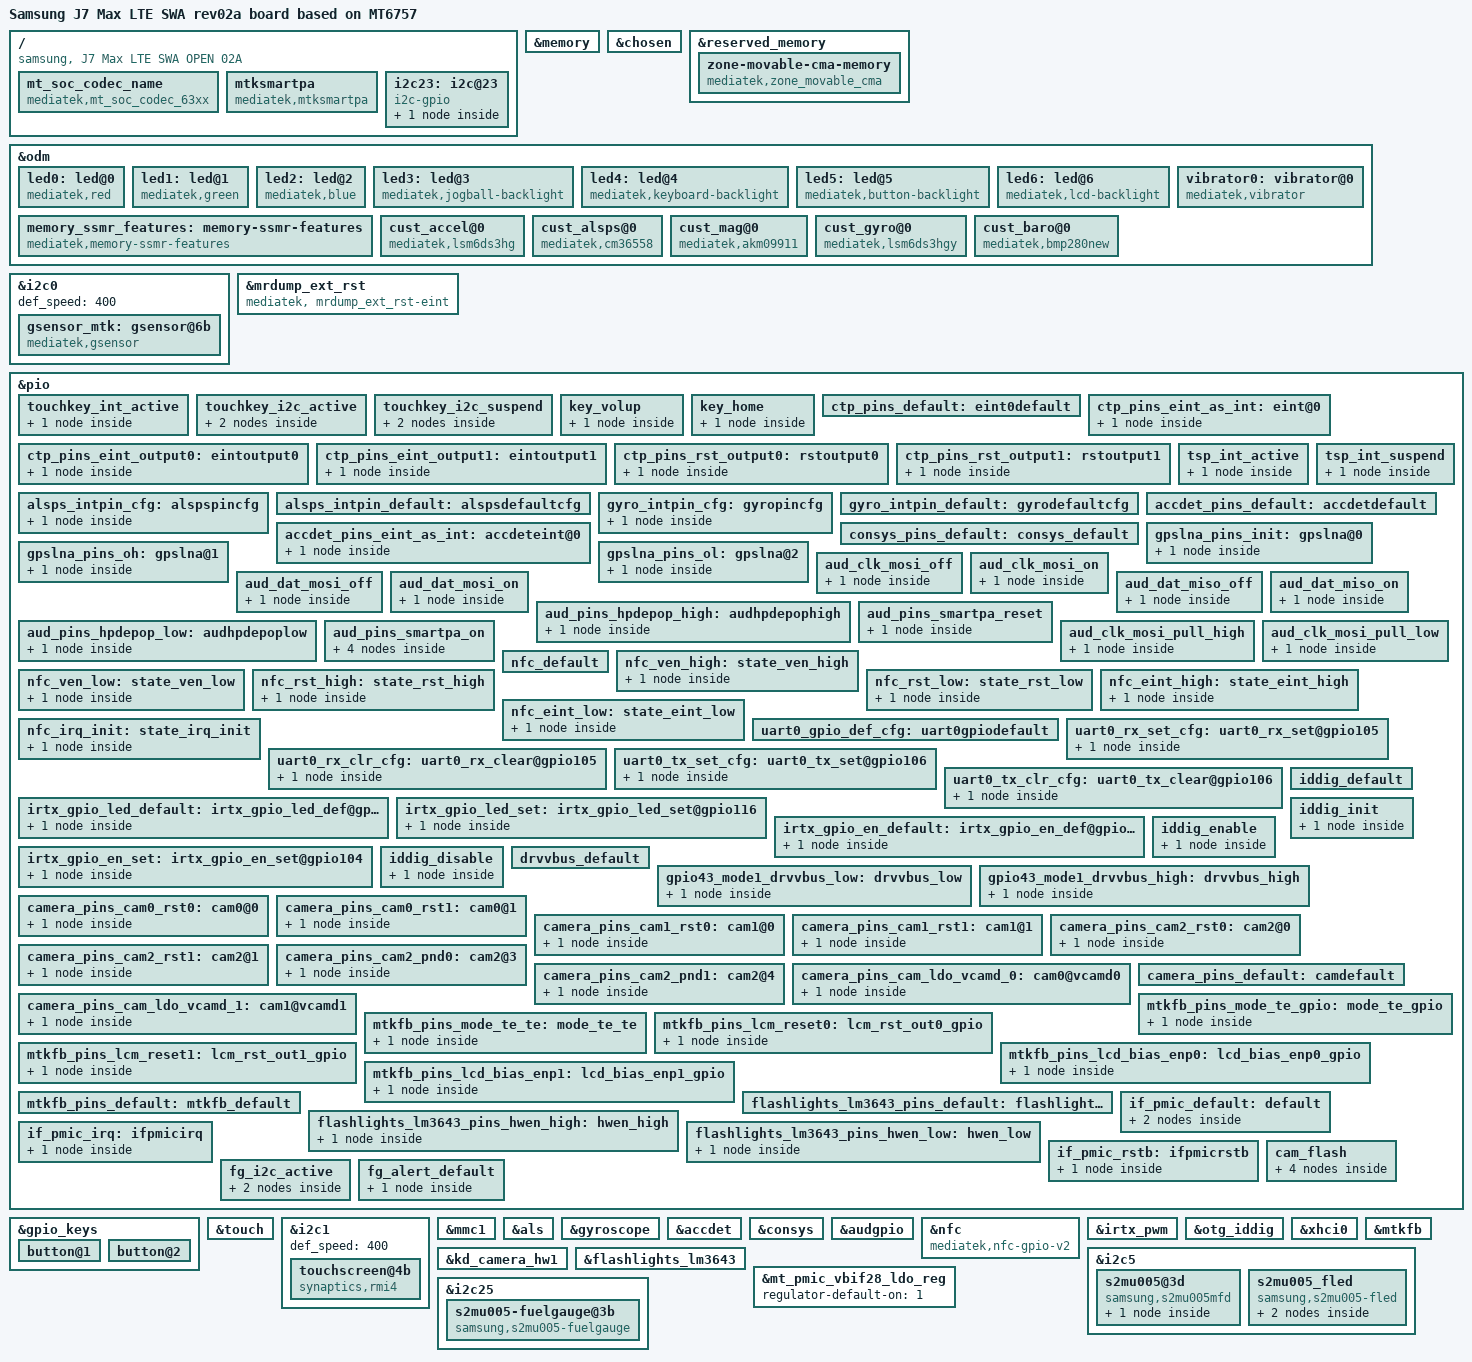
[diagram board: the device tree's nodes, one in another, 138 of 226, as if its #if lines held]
/*
 * Copyright (C) 2016 MediaTek Inc.
 *
 * This program is free software; you can redistribute it and/or modify
 * it under the terms of the GNU General Public License version 2 as
 * published by the Free Software Foundation.
 *
 * This program is distributed in the hope that it will be useful,
 * but WITHOUT ANY WARRANTY; without even the implied warranty of
 * MERCHANTABILITY or FITNESS FOR A PARTICULAR PURPOSE.
 * See http://www.gnu.org/licenses/gpl-2.0.html for more details.
 */

#include <generated/autoconf.h>
/dts-v1/;

#ifdef CONFIG_MTK_DTBO_FEATURE
/plugin/;
#include <dt-bindings/interrupt-controller/irq.h>
#include <dt-bindings/interrupt-controller/arm-gic.h>
#include <dt-bindings/mmc/mt6757-msdc.h>
#include <dt-bindings/pinctrl/mt6757-pinfunc.h>
#else
#include "mt6757.dts"
#include "titan6757_phone_gpio.dtsi"
#include <dt-bindings/input/input.h>
#include "battery_data_j7max_common.dtsi"
#endif

/ {
	model = "Samsung J7 Max LTE SWA rev02a board based on MT6757";
	model_info-chip = <6757>;
	model_info-platform = "android";
	model_info-subtype = "mediatek";
	model_info-hw_rev = <5>;
	model_info-hw_rev_end = <255>;
	compatible = "samsung, J7 Max LTE SWA OPEN 02A", "mediatek,MT6757";
};

&memory {
	device_type = "memory";
	reg = <0 0x40000000 0 0x1e605000>,
		  <1 0x00000000 0 0x20000000>;
};

/* chosen */
&chosen {
	bootargs = "console=tty0 console=ttyMT0,921600n1 root=/dev/ram initrd=0x45000000,
	0x1000000 loglevel=8 androidboot.selinux=permissive androidboot.hardware=mt6757";
	/* fpga may has no lk, we need to specify display info here */
	/* fb buffer is reserved using this dts by memory node above */
	atag,videolfb-fb_base_h = <0x0>;
	atag,videolfb-fb_base_l = <0x5e605000>;
	atag,videolfb-islcmfound = <1>;
	/* because no lk, so lcm is not inited */
	atag,videolfb-islcm_inited = <0>;
	atag,videolfb-fps= <6000>;
	atag,videolfb-vramSize= <0x017bb000>;
	atag,videolfb-lcmname= "nt35695_fhd_dsi_cmd_truly_nt50358_drv";
};


&reserved_memory {
	#address-cells = <2>;
	#size-cells = <2>;
	ranges;

	zone-movable-cma-memory {
		compatible = "mediatek,zone_movable_cma";
		size = <0 0x18000000>;
		/* 256MB alignment */
		alignment = <0 0x1000000>;
		alloc-ranges = <0 0xc0000000 1 0x00000000>;
	};
};

&odm {
	led0:led@0 {
		compatible = "mediatek,red";
		led_mode = <0>;
		data = <1>;
		pwm_config = <0 0 0 0 0>;
	};
	led1:led@1 {
		compatible = "mediatek,green";
		led_mode = <0>;
		data = <1>;
		pwm_config = <0 0 0 0 0>;
	};
	led2:led@2 {
		compatible = "mediatek,blue";
		led_mode = <0>;
		data = <1>;
		pwm_config = <0 0 0 0 0>;
	};
	led3:led@3 {
		compatible = "mediatek,jogball-backlight";
		led_mode = <0>;
		data = <1>;
		pwm_config = <0 0 0 0 0>;
	};
	led4:led@4 {
		compatible = "mediatek,keyboard-backlight";
		led_mode = <0>;
		data = <1>;
		pwm_config = <0 0 0 0 0>;
	};
	led5:led@5 {
		compatible = "mediatek,button-backlight";
		led_mode = <0>;
		data = <1>;
		pwm_config = <0 0 0 0 0>;
	};
	led6:led@6 {
		compatible = "mediatek,lcd-backlight";
		led_mode = <4>;
		data = <1>;
		pwm_config = <0 0 0 0 0>;
	};
	vibrator0:vibrator@0 {
		compatible = "mediatek,vibrator";
		vib_timer = <25>;
		vib_limit = <9>;
		vib_vol= <9>;
	};
	memory_ssmr_features: memory-ssmr-features {
		compatible = "mediatek,memory-ssmr-features";
		svp-size = <0 0x10000000>;
		iris-recognition-size = <0 0>;
		2d_fr-size = <0 0>;
		tui-size = <0 0x4000000>;
		wfd-size = <0 0x4000000>;
		prot-sharedmem-size = <0 0>;
	};
/*  start sensor */

	cust_accel@0 {
		compatible = "mediatek,lsm6ds3hg";
		i2c_num	= <0>;
		i2c_addr = <0x6b 0 0 0>;
		direction = <5>;
		power_id = <0xffff>;
		power_vol = <0>;
		firlen = <16>;
		is_batch_supported = <0>;
	};
	cust_alsps@0 {
		compatible = "mediatek,cm36558";
		i2c_num	= <1>;
		i2c_addr = <0x51 0 0 0>;
		polling_mode_ps	= <0>;
		polling_mode_als = <1>;
		power_id = <0xffff>;
		power_vol = <0>;
		als_level = <0 328 861 1377 3125 7721 7767 12621 23062 28430 33274 47116 57694 57694 65535>;
		als_value = <0 133 304 502 1004 2005 3058 5005 8008 10010 12000 16000 20000 20000 20000 20000>;
		ps_threshold_high = <26>;
		ps_threshold_low = <21>;
		is_batch_supported_ps = <0>;
		is_batch_supported_als = <0>;
	};
	cust_mag@0 {
		compatible			= "mediatek,akm09911";
		i2c_num				= <1>;
		/* i2c_addr			= <0x0D 0 0 0>; */
		direction			= <7>;
		power_id			= <0xffff>;
		power_vol			= <0>;
		/* is_batch_supported		= <0>; */
	};

	cust_gyro@0 {
		compatible			= "mediatek,lsm6ds3hgy";
		i2c_num				= <1>;
		/* i2c_addr			= <0x68 0 0 0>; */
		direction			= <7>;
		power_id			= <0xffff>;
		power_vol			= <0>;
		firlen				= <0>;
		is_batch_supported		= <0>;
	};

	cust_baro@0 {
		compatible			= "mediatek,bmp280new";
		i2c_num				= <1>;
		/* i2c_addr			= <0x77 0 0 0>; */
		direction			= <0>;
		power_id			= <0xffff>;
		power_vol			= <0>;
		firlen				= <32>;
		is_batch_supported		= <0>;
	};
/* end sensor */
};

&i2c0 {
	#address-cells = <1>;
	#size-cells = <0>;
	def_speed = <400>;
	gsensor_mtk:gsensor@6b {
		compatible = "mediatek,gsensor";
		reg = <0x6b>;
		direction = <5>;
		power_id = <0xffff>;
		power_vol = <0>;
		firlen = <16>;
		is_batch_supported = <0>;
		status = "okay";
	};
};

/ {
	/* start audio */
	mt_soc_codec_name {
		compatible = "mediatek,mt_soc_codec_63xx";
		use_hp_depop_flow = <1>; /* select 1: use, 0: not use */
		use_ul_260k = <0>; /* select 1: use, 0: not use */
		clk_src = <0>; /* select 1: external, 0: pmic internal */
	};

	mtksmartpa {
		compatible = "mediatek,mtksmartpa";
	};
	/* end audio */

	/*i2c-gpio and touch key*/
	i2c23: i2c@23 { /* SW I2C */
		cell-index = <23>;
		compatible = "i2c-gpio";
		gpios = <&pio 190 0 /* sda */
				&pio 191 0 /* scl */
				>;
		//i2c-gpio,sda-open-drain = <1>;
		//i2c-gpio,scl-open-drain = <1>;
		#i2c-gpio,delay-us = <2>;
		#address-cells = <1>;
		#size-cells = <0>;
		status = "okay";

		tc305k@20 {
			compatible = "coreriver,tc300-keypad";
			reg = <0x20>;
			interrupt-parent = <&eintc>;
			interrupts = <11 IRQ_TYPE_LEVEL_LOW>;	/*gpionum trigger*/
			pinctrl-names = "touchkey_active", "touchkey_suspend";
			pinctrl-0 = <&touchkey_i2c_active &touchkey_int_active>;
			pinctrl-1 = <&touchkey_i2c_suspend>;
			coreriver,sda-gpio = <&pio 190 0>;	/*i2c-sda*/
			coreriver,scl-gpio = <&pio 191 0>;	/*i2c-scl*/
			coreriver,irq-gpio = <&pio 11 0>;	/*irq*/
			coreriver,tkey_en-gpio = <&pio 15 0>;	/*touch-en*/
			//coreriver,sub-det-gpio = <&pio 37 0>;
			coreriver,i2c-gpio = "true";
			coreriver,fw_name = "coreriver/tc305k_j7maxlte.fw";
			coreriver,sensing_ch_num = <0x4>;
			coreriver,tsk_ic_num = <0x1>;
			coreriver,use_bitmap = <1>;
		};
	};
};

&mrdump_ext_rst {
	compatible = "mediatek, mrdump_ext_rst-eint";
	source = "SYSRST";
	mode = "RST";
	status = "okay";
};

&pio {
	touchkey_int_active: touchkey_int_active {
		pins_cmd_dat {
			pins = <PINMUX_GPIO11__FUNC_GPIO11>;	/*touchkey eint pin*/
			slew-rate = <0>;
			/*bias-pull-up = <11>; */
			bias-pull-up = <1>;
		};
	};
	touchkey_i2c_active: touchkey_i2c_active {
		pins_cmd_dat1 {
			pins = <PINMUX_GPIO190__FUNC_GPIO190>;	/*touchkey i2c pin*/
			slew-rate = <0>;
			bias-disable;
		};
		pins_cmd_dat2 {
			pins = <PINMUX_GPIO191__FUNC_GPIO191>;	/*touchkey i2c pin*/
			slew-rate = <0>;
			bias-disable;
		};
	};
	touchkey_i2c_suspend: touchkey_i2c_suspend {
		pins_cmd_dat1 {
			pins = <PINMUX_GPIO190__FUNC_GPIO190>;	/*touchkey i2c pin*/
			slew-rate = <0>;
			bias-disable;
		};
		pins_cmd_dat2 {
			pins = <PINMUX_GPIO191__FUNC_GPIO191>;	/*touchkey i2c pin*/
			slew-rate = <0>;
			bias-disable;
		};
	};
};
/*end*/

/* gpio_keys start */
&gpio_keys {
	pinctrl-names = "default";
	pinctrl-0 = <&key_volup &key_home>;
	name = "gpio_keys";
	button@1 {
		label = "gpio-keys: KEY_VOLUMEUP";
		linux,code = <KEY_VOLUMEUP>;
		interrupt-parent = <&eintc>;
		interrupts = <104 IRQ_TYPE_EDGE_FALLING>;
		debounce-interval = <64>;
		gpios = <&pio 104 1>;
		status = "okay";
	};
	button@2 {
		label = "gpio-keys: KEY_HOME";
		linux,code = <KEY_HOME>;
		interrupt-parent = <&eintc>;
		interrupts = <42 IRQ_TYPE_EDGE_FALLING>;
		debounce-interval = <64>;
		gpios = <&pio 42 1>;
		gpio-key,wakeup = <1>;
		status = "okay";
	};
};

&pio {
	key_volup: key_volup {
		pins_cmd_dat {
			pins = <PINMUX_GPIO104__FUNC_GPIO104>;
			slew-rate = <0>;
			/* bias-pull-up = <00>; */
			bias-pull-up = <MTK_PUPD_SET_R1R0_00>;
		};
	};
	key_home: key_home{
		pins_cmd_dat {
			pins = <PINMUX_GPIO42__FUNC_GPIO42>;
			slew-rate = <0>;
			/* bias-pull-up = <00>; */
			bias-pull-up = <MTK_PUPD_SET_R1R0_00>;
		};
	};
};
/* gpio_keys end */

/* TOUCH start */
&touch {
	tpd-resolution = <1080 1920>;
	use-tpd-button = <0>;
	tpd-key-num = <3>;
	tpd-key-local= <139 172 158 0>;
	tpd-key-dim-local = <90 883 100 40 230 883 100 40 370 883 100 40 0 0 0 0>;
	tpd-max-touch-num = <5>;
	tpd-filter-enable = <1>;
	tpd-filter-pixel-density = <146>;
	tpd-filter-custom-prameters = <0 0 0 0 0 0 0 0 0 0 0 0>;
	tpd-filter-custom-speed = <0 0 0>;
	pinctrl-names = "default", "state_eint_as_int", "state_eint_output0", "state_eint_output1",
		"state_rst_output0", "state_rst_output1";
	pinctrl-0 = <&ctp_pins_default>;
	pinctrl-1 = <&ctp_pins_eint_as_int>;
	pinctrl-2 = <&ctp_pins_eint_output0>;
	pinctrl-3 = <&ctp_pins_eint_output1>;
	pinctrl-4 = <&ctp_pins_rst_output0>;
	pinctrl-5 = <&ctp_pins_rst_output1>;
	status = "okay";
};
&pio {
	ctp_pins_default: eint0default {
	};
	ctp_pins_eint_as_int: eint@0 {
		pins_cmd_dat {
			pins = <PINMUX_GPIO1__FUNC_GPIO1>;
			slew-rate = <0>;
			bias-disable;
		};
	};
	ctp_pins_eint_output0: eintoutput0 {
		pins_cmd_dat {
			pins = <PINMUX_GPIO1__FUNC_GPIO1>;
			slew-rate = <1>;
			output-low;
		};
	};
	ctp_pins_eint_output1: eintoutput1 {
		pins_cmd_dat {
			pins = <PINMUX_GPIO1__FUNC_GPIO1>;
			slew-rate = <1>;
			output-high;
		};
	};
	ctp_pins_rst_output0: rstoutput0 {
		pins_cmd_dat {
			pins = <PINMUX_GPIO10__FUNC_GPIO10>;
			slew-rate = <1>;
			output-low;
		};
	};
	ctp_pins_rst_output1: rstoutput1 {
		pins_cmd_dat {
			pins = <PINMUX_GPIO10__FUNC_GPIO10>;
			slew-rate = <1>;
			output-high;
		};
	};
};
/* TOUCH end */
/* TOUCH start */
&i2c1 {
	#address-cells = <1>;
	#size-cells = <0>;
	def_speed = <400>;
	touchscreen@4b {
			compatible = "synaptics,rmi4";
			reg = <0x4b>;
			pinctrl-names = "tsp_int_active", "tsp_int_suspend";
			pinctrl-0 = <&tsp_int_active>;
			pinctrl-1 = <&tsp_int_suspend>;
			interrupt-parent = <&eintc>;
			interrupts = <1 IRQ_TYPE_EDGE_FALLING>;

			synaptics,irq_gpio = <&pio 1 0>;
			synaptics,tsp_rst = <&pio 18 0>;
			synaptics,irq_type = <8200>;
			synaptics,max_coords = <1080 1920>;	/* x y */
			synaptics,num_lines = <30 18>;		/* rx tx */
			synaptics,project_name = "J7max";
			synaptics,irq-on-state = <0>;
			synaptics,ub-i2c-addr = <0x2c>;
			synaptics,power-delay-ms = <200>;
			synaptics,reset-delay-ms = <200>;
			synaptics,reset-on-state = <0>;
			synaptics,reset-active-ms = <20>;
			synaptics,firmware_name = "tsp_synaptics/td4303_j7maxlte.fw";
			synaptics,firmware_name_bl = "tsp_synaptics/td4300_on7xelte_recovery.fw";
			/* uncomment and update line below as appropriate if there are 0D buttons */
			/* synaptics,cap-button-codes = <102 158>; */
			/* uncomment and update lines below as appropriate if there are virtual buttons */
			/* synaptics,vir-button-codes = <102 100 900 100 60 158 300 900 100 60>; */
			/* synaptics,max-y-for-2d = <800>; */
		};
};

&pio {
	tsp_int_active: tsp_int_active {
		pins_cmd_dat {
			pins = <PINMUX_GPIO1__FUNC_GPIO1>;	/*touchkey eint pin*/
			slew-rate = <0>;
			bias-disable;
		};
	};
	tsp_int_suspend: tsp_int_suspend {
		pins_cmd_dat {
			pins = <PINMUX_GPIO1__FUNC_GPIO1>;	/*touchkey eint pin*/
			slew-rate = <0>;
			bias-disable;
		};
	};
};
/* TOUCH end */

&mmc1 {
	clk_src = /bits/ 8 <MSDC30_CLKSRC_200MHZ>;
	bus-width = <4>;
	max-frequency = <200000000>;
	msdc-sys-suspend;
	cap-sd-highspeed;
	sd-uhs-sdr12;
	sd-uhs-sdr25;
	sd-uhs-sdr50;
	sd-uhs-sdr104;
	sd-uhs-ddr50;
	pinctl = <&mmc1_pins_default>;
	pinctl_sdr104 = <&mmc1_pins_sdr104>;
	pinctl_sdr50 = <&mmc1_pins_sdr50>;
	pinctl_ddr50 = <&mmc1_pins_ddr50>;
	register_setting = <&mmc1_register_setting_default>;
	host_function = /bits/ 8 <MSDC_SD>;
	cd_level = /bits/ 8 <MSDC_CD_LOW>;
	cd-gpios = <&pio 5 0>;
	status = "okay";
	vmmc-supply = <&mt_pmic_vmch_ldo_reg>;
	vqmmc-supply = <&mt_pmic_vmc_ldo_reg>;
};

/* sensor gpio standization */
&pio {
	alsps_intpin_cfg: alspspincfg {

		pins_cmd_dat {
			pins = <PINMUX_GPIO6__FUNC_GPIO6>;
			slew-rate = <0>;
			bias-pull-up = <00>;
		};
	};

	alsps_intpin_default: alspsdefaultcfg {

	};

	gyro_intpin_cfg: gyropincfg {

		pins_cmd_dat {
			pins = <PINMUX_GPIO4__FUNC_GPIO4>;
			slew-rate = <0>;
			bias-pull-down = <00>;
		};
	};

	gyro_intpin_default: gyrodefaultcfg {

	};
};

&als {
	pinctrl-names = "pin_default", "pin_cfg";
	pinctrl-0 = <&alsps_intpin_default>;
	pinctrl-1 = <&alsps_intpin_cfg>;
	status = "okay";
};

&gyroscope {
	pinctrl-names = "pin_default", "pin_cfg";
	pinctrl-0 = <&gyro_intpin_default>;
	pinctrl-1 = <&gyro_intpin_cfg>;
	status = "okay";
};
/* sensor end */

/* accdet start */
&accdet {
		/* accdet micbias voltage: 0x07,2.7v;0x05,2.5v;0x02,1.9v */
		accdet-mic-vol = <7>;
		headset-mode-setting = <0x500 0x500 1 0x1F0 0x800 0x800 0x20>;
		accdet-plugout-debounce = <256>;
		/*1:ACC mode, 2:low cost without in bias, 6:low cost with in bias*/
		accdet-mic-mode = <1>;
		/* eint_level_trigger: 8,LEVEL_LOW(default);4,LEVEL_HIGH;others,LEVEL_LOW */
		headset-eint-level-pol = <8>;
		/*min_3pole--max_3pole--min_4pole--max_4pole--vol_bias*/
		headset-vol-threshold = <0 590 591 1680 2700>;
		/*0--MD_MAX--UP_MAX--DW_MAX*/
		headset-three-key-threshold = <0 80 220 400>;
		headset-three-key-threshold-CDD = <0 121 192 600>;
		/*0--MD_MAX--VOICE_MAX--UP_MAX--DW_MAX*/
		headset-four-key-threshold = <0 58 121 192 400>;
		/* ACCDET GPIO standardization ACC mode */
		pinctrl-names = "default", "state_eint_as_int";
		pinctrl-0 = <&accdet_pins_default>;
		pinctrl-1 = <&accdet_pins_eint_as_int>;
		status = "okay";
};
&pio {
       accdet_pins_default: accdetdefault {
	 };
	 accdet_pins_eint_as_int: accdeteint@0 {
	     pins_cmd_dat {
		  pins = <PINMUX_GPIO9__FUNC_GPIO9>;
		  slew-rate = <0>;
		  bias-disable;
		 };
	 };
};
/* accdet end*/

/* CONSYS GPIO standardization */
&pio {
	consys_pins_default: consys_default {
	};
	gpslna_pins_init: gpslna@0 {
		pins_cmd_dat {
			pins = <PINMUX_GPIO114__FUNC_GPIO114>;
			slew-rate = <0>;
			bias-disable;
			output-low;
		};
	};
	gpslna_pins_oh: gpslna@1 {
		pins_cmd_dat {
			pins = <PINMUX_GPIO114__FUNC_GPIO114>;
			slew-rate = <1>;
			output-high;
		};
	};
	gpslna_pins_ol: gpslna@2 {
		pins_cmd_dat {
			pins = <PINMUX_GPIO114__FUNC_GPIO114>;
			slew-rate = <1>;
			output-low;
		};
	};
};
&consys {
	pinctrl-names = "default", "gps_lna_state_init", "gps_lna_state_oh", "gps_lna_state_ol";
	pinctrl-0 = <&consys_pins_default>;
	pinctrl-1 = <&gpslna_pins_init>;
	pinctrl-2 = <&gpslna_pins_oh>;
	pinctrl-3 = <&gpslna_pins_ol>;
	status = "okay";
};
/* CONSYS end */

/* AUDIO GPIO standardization */
&audgpio {
	pinctrl-names = "aud_clk_mosi_off",
			"aud_clk_mosi_on",
			"aud_dat_mosi_off",
			"aud_dat_mosi_on",
			"aud_dat_miso_off",
			"aud_dat_miso_on",
			"hpdepop-pullhigh",
			"hpdepop-pulllow",
			"aud_smartpa_reset",
			"aud_smartpa_on",
			"aud_clk_mosi_pull_high",
			"aud_clk_mosi_pull_low";
	pinctrl-0 = <&aud_clk_mosi_off>;
	pinctrl-1 = <&aud_clk_mosi_on>;
	pinctrl-2 = <&aud_dat_mosi_off>;
	pinctrl-3 = <&aud_dat_mosi_on>;
	pinctrl-4 = <&aud_dat_miso_off>;
	pinctrl-5 = <&aud_dat_miso_on>;
	pinctrl-6 = <&aud_pins_hpdepop_high>;
	pinctrl-7 = <&aud_pins_hpdepop_low>;
	pinctrl-8 = <&aud_pins_smartpa_reset>;
	pinctrl-9 = <&aud_pins_smartpa_on>;
	pinctrl-10 = <&aud_clk_mosi_pull_high>;
	pinctrl-11 = <&aud_clk_mosi_pull_low>;
	status = "okay";
};

&pio {
	aud_clk_mosi_off: aud_clk_mosi_off {
		pins_cmd0_dat {
			pins = <PINMUX_GPIO149__FUNC_GPIO149>;
		};
	};

	aud_clk_mosi_on: aud_clk_mosi_on {
		pins_cmd0_dat {
			pins = <PINMUX_GPIO149__FUNC_AUD_CLK_MOSI>;
		};
	};

	aud_dat_mosi_off: aud_dat_mosi_off {
		pins_cmd1_dat {
			pins = <PINMUX_GPIO150__FUNC_GPIO150>;
			slew-rate = <0>;
			bias-pull-up = <00>;
		};
	};

	aud_dat_mosi_on: aud_dat_mosi_on {
		pins_cmd1_dat {
			pins = <PINMUX_GPIO150__FUNC_AUD_DAT_MOSI>;
		};
	};

	aud_dat_miso_off: aud_dat_miso_off {
		pins_cmd2_dat {
			pins = <PINMUX_GPIO151__FUNC_GPIO151>;
		};
	};

	aud_dat_miso_on: aud_dat_miso_on {
		pins_cmd2_dat {
			pins = <PINMUX_GPIO151__FUNC_AUD_DAT_MISO>;
		};
	};

	aud_pins_hpdepop_high: audhpdepophigh {
		pins_cmd_dat {
			pins = <PINMUX_GPIO14__FUNC_GPIO14>;
			slew-rate = <1>;
			output-high;
		};
	};

	aud_pins_hpdepop_low: audhpdepoplow {
		pins_cmd_dat {
			pins = <PINMUX_GPIO14__FUNC_GPIO14>;
			slew-rate = <1>;
			output-low;
		};
	};

	aud_pins_smartpa_reset: aud_pins_smartpa_reset {
		pins_cmd0_dat {
			pins = <PINMUX_GPIO190__FUNC_GPIO190>;
		};
	};

	aud_pins_smartpa_on: aud_pins_smartpa_on {
		pins_cmd0_dat {
			pins = <PINMUX_GPIO16__FUNC_I2S0_DI>;
		};
		pins_cmd1_dat {
			pins = <PINMUX_GPIO26__FUNC_I2S3_BCK>;
		};
		pins_cmd2_dat {
			pins = <PINMUX_GPIO27__FUNC_I2S3_LRCK>;
		};
		pins_cmd3_dat {
			pins = <PINMUX_GPIO28__FUNC_I2S3_DO>;
		};
	};

	aud_clk_mosi_pull_high: aud_clk_mosi_pull_high {
		pins_cmd_dat {
			pins = <PINMUX_GPIO149__FUNC_GPIO149>;
			slew-rate = <1>;
			output-high;
		};
	};

	aud_clk_mosi_pull_low: aud_clk_mosi_pull_low {
		pins_cmd_dat {
			pins = <PINMUX_GPIO149__FUNC_GPIO149>;
			slew-rate = <1>;
			output-low;
		};
	};
};
/* AUDIO end */

&mmc1 {
	cd-gpios = <&pio 5 0>;
	status = "okay";
};

&nfc {
	compatible = "mediatek,nfc-gpio-v2";
	gpio-ven = <&pio 15 0>;
	gpio-rst = <&pio 25 0>;
	gpio-eint = <&pio 14 0>;
	gpio-irq = <&pio 13 0>;
	gpio-osc = <&pio 99 0>;
	pinctrl-names = "default", "ven_high", "ven_low", "rst_high", "rst_low",
	"eint_high", "eint_low", "irq_init";
	pinctrl-0 = <&nfc_default>;
	pinctrl-1 = <&nfc_ven_high>;
	pinctrl-2 = <&nfc_ven_low>;
	pinctrl-3 = <&nfc_rst_high>;
	pinctrl-4 = <&nfc_rst_low>;
	pinctrl-5 = <&nfc_eint_high>;
	pinctrl-6 = <&nfc_eint_low>;
	pinctrl-7 = <&nfc_irq_init>;
	status = "okay";
};

/* NFC GPIO standardization */
&pio {
	nfc_default: nfc_default {

	};

	nfc_ven_high: state_ven_high {
		pins_cmd_dat {
			pins = <PINMUX_GPIO15__FUNC_GPIO15>;
			slew-rate = <1>;
			output-high;
		};
	};

	nfc_ven_low: state_ven_low {
		pins_cmd_dat {
			pins = <PINMUX_GPIO15__FUNC_GPIO15>;
			slew-rate = <1>;
			output-low;
		};
	};

	nfc_rst_high: state_rst_high {
		pins_cmd_dat {
			pins = <PINMUX_GPIO25__FUNC_GPIO25>;
			slew-rate = <1>;
			output-high;
		};
	};

	nfc_rst_low: state_rst_low {
		pins_cmd_dat {
			pins = <PINMUX_GPIO25__FUNC_GPIO25>;
			slew-rate = <1>;
			output-low;
		};
	};

	nfc_eint_high: state_eint_high {
		pins_cmd_dat {
			pins = <PINMUX_GPIO14__FUNC_GPIO14>;
			slew-rate = <1>;
			output-high;
		};
	};

	nfc_eint_low: state_eint_low {
		pins_cmd_dat {
			pins = <PINMUX_GPIO14__FUNC_GPIO14>;
			slew-rate = <1>;
			output-low;
		};
	};

	nfc_irq_init: state_irq_init {
		pins_cmd_dat {
			pins = <PINMUX_GPIO13__FUNC_GPIO13>;
			slew-rate = <0>;
			bias-pull-down = <00>;
		};
	};
};
/* NFC end */

/* UART GPIO */
/*
*&apuart0 {
*	pinctrl-names = "uart0_gpio_default",
*			"uart0_rx_set",
*			"uart0_rx_clear",
*			"uart0_tx_set",
*			"uart0_tx_clear";
*	pinctrl-0 = <&uart0_gpio_def_cfg>;
*	pinctrl-1 = <&uart0_rx_set_cfg>;
*	pinctrl-2 = <&uart0_rx_clr_cfg>;
*	pinctrl-3 = <&uart0_tx_set_cfg>;
*	pinctrl-4 = <&uart0_tx_clr_cfg>;
*	status = "okay";
*};
*/
&pio {
	/* UART GPIO Settings - Start */
	/* UART0: rx set, rx clear, tx clear, tx clear*/
	uart0_gpio_def_cfg:uart0gpiodefault {

	};
	uart0_rx_set_cfg:uart0_rx_set@gpio105 {
		pins_cmd_dat {
			pins = <PINMUX_GPIO105__FUNC_URXD0>;
		};
	};
	uart0_rx_clr_cfg:uart0_rx_clear@gpio105  {
		pins_cmd_dat {
			pins = <PINMUX_GPIO105__FUNC_GPIO105>;
			slew-rate = <1>;
			output-high;
		};
	};
	uart0_tx_set_cfg:uart0_tx_set@gpio106  {
		pins_cmd_dat {
			pins = <PINMUX_GPIO106__FUNC_UTXD0>;
		};
	};
	uart0_tx_clr_cfg:uart0_tx_clear@gpio106  {
		pins_cmd_dat {
			pins = <PINMUX_GPIO106__FUNC_GPIO106>;
			slew-rate = <1>;
			output-high;
		};
	};
};/* UART GPIO end */

/* IRTX GPIO end */
&irtx_pwm {
	pinctrl-names = "irtx_gpio_led_default",
			"irtx_gpio_led_set",
			"irtx_gpio_en_default",
			"irtx_gpio_en_set";

	pinctrl-0 = <&irtx_gpio_led_default>;
	pinctrl-1 = <&irtx_gpio_led_set>;
	pinctrl-2 = <&irtx_gpio_en_default>;
	pinctrl-3 = <&irtx_gpio_en_set>;
	status = "okay";
};
&pio {
	/* IRTX GPIO Settings -Start */
	/* default: GPIO0, output, high */
	irtx_gpio_led_default:irtx_gpio_led_def@gpio116 {
		pins_cmd_dat {
			pins = <PINMUX_GPIO116__FUNC_GPIO116>;
			slew-rate = <1>;
			bias-disable;
			output-low;
			input-schmitt-enable = <0>;
		};
	};

	irtx_gpio_led_set:irtx_gpio_led_set@gpio116 {
		pins_cmd_dat {
			pins = <PINMUX_GPIO116__FUNC_PWM_C>;
			slew-rate = <1>;
			output-high;
		};
	};

	irtx_gpio_en_default:irtx_gpio_en_def@gpio104 {
		pins_cmd_dat {
			pins = <PINMUX_GPIO104__FUNC_GPIO104>;
			slew-rate = <1>;
			bias-disable;
			output-low;
			input-schmitt-enable = <0>;
		};
	};

	irtx_gpio_en_set:irtx_gpio_en_set@gpio104 {
		pins_cmd_dat {
			pins = <PINMUX_GPIO104__FUNC_GPIO104>;
			slew-rate = <1>;
			output-high;
		};
	};


}; /* IRTX GPIO Settings -End */

&pio {
	iddig_default: iddig_default {
	};
	iddig_init: iddig_init {
		pins_cmd_dat {
			pins = <PINMUX_GPIO42__FUNC_IDDIG>;
			input-enable;
			slew-rate = <0>;
			bias-pull-up = <00>;
		};
	};
	iddig_enable: iddig_enable {
		pins_cmd_dat {
			pins = <PINMUX_GPIO42__FUNC_IDDIG>;
			input-enable;
			slew-rate = <0>;
			bias-pull-up = <00>;
		};
	};
	iddig_disable: iddig_disable {
		pins_cmd_dat {
			pins = <PINMUX_GPIO42__FUNC_GPIO42>;
			input-disable;
			slew-rate = <1>;
			output-low;
		};
	};
};

&pio {
	drvvbus_default: drvvbus_default {
	};

	gpio43_mode1_drvvbus_low: drvvbus_low {
		pins_cmd_dat {
			pins = <PINMUX_GPIO43__FUNC_USB_DRVVBUS>;
			slew-rate = <1>;
			output-low;
		};
	};

	gpio43_mode1_drvvbus_high: drvvbus_high {
		pins_cmd_dat {
			pins = <PINMUX_GPIO43__FUNC_USB_DRVVBUS>;
			slew-rate = <1>;
			output-high;
		};
	};
};

&otg_iddig {
	pinctrl-names = "iddig_default", "iddig_init", "iddig_enable", "iddig_disable";
	pinctrl-0 = <&iddig_default>;
	pinctrl-1 = <&iddig_init>;
	pinctrl-2 = <&iddig_enable>;
	pinctrl-3 = <&iddig_disable>;
	status = "okay";
};

&xhci0 {
	pinctrl-names = "drvvbus_default", "drvvbus_low", "drvvbus_high";
	pinctrl-0 = <&drvvbus_default>;
	pinctrl-1 = <&gpio43_mode1_drvvbus_low>;
	pinctrl-2 = <&gpio43_mode1_drvvbus_high>;
	status = "okay";
};
/* CAMERA GPIO standardization */
&pio {
	camera_pins_cam0_rst0: cam0@0 {
		pins_cmd_dat {
			pins = <PINMUX_GPIO110__FUNC_GPIO110>;
			slew-rate = <1>; /*direction 0:in, 1:out*/
			output-low;/*direction out used only. output_low or high*/
		};
	};
	camera_pins_cam0_rst1: cam0@1 {
		pins_cmd_dat {
			pins = <PINMUX_GPIO110__FUNC_GPIO110>;
			slew-rate = <1>;
			output-high;
		};
	};
	camera_pins_cam1_rst0: cam1@0 {
		pins_cmd_dat {
			pins = <PINMUX_GPIO111__FUNC_GPIO111>;
			slew-rate = <1>; /*direction 0:in, 1:out*/
			output-low;/*direction out used only. output_low or high*/
		};
	};
	camera_pins_cam1_rst1: cam1@1 {
		pins_cmd_dat {
			pins = <PINMUX_GPIO111__FUNC_GPIO111>;
			slew-rate = <1>;
			output-high;
		};
	};
	camera_pins_cam2_rst0: cam2@0 {
		pins_cmd_dat {
			pins = <PINMUX_GPIO90__FUNC_GPIO90>;
			slew-rate = <1>;
			output-low;
		};
	};
	camera_pins_cam2_rst1: cam2@1 {
		pins_cmd_dat {
			pins = <PINMUX_GPIO90__FUNC_GPIO90>;
			slew-rate = <1>;
			output-high;
		};
	};
	camera_pins_cam2_pnd0: cam2@3 {
		pins_cmd_dat {
			pins = <PINMUX_GPIO89__FUNC_GPIO89>;
			slew-rate = <1>;
			output-low;
		};
	};
	camera_pins_cam2_pnd1: cam2@4 {
		pins_cmd_dat {
			pins = <PINMUX_GPIO89__FUNC_GPIO89>;
			slew-rate = <1>;
			output-high;
		};
	};
	camera_pins_cam_ldo_vcamd_0: cam0@vcamd0 {
		pins_cmd_dat {
			pins = <PINMUX_GPIO23__FUNC_GPIO23>;
			slew-rate = <1>;
			output-low;
		};
	};
	camera_pins_cam_ldo_vcamd_1: cam1@vcamd1 {
		pins_cmd_dat {
			pins = <PINMUX_GPIO23__FUNC_GPIO23>;
			slew-rate = <1>;
			output-high;
		};
	};
	camera_pins_default: camdefault {
	};

};

&kd_camera_hw1 {
	pinctrl-names = "default",
			"cam0_rst0", "cam0_rst1", "cam1_rst0", "cam1_rst1",
			"cam2_rst0", "cam2_rst1", "cam2_pnd0", "cam2_pnd1",
			"cam_ldo_vcamd_0", "cam_ldo_vcamd_1";

	pinctrl-0 = <&camera_pins_default>;
	pinctrl-1 = <&camera_pins_cam0_rst0>;
	pinctrl-2 = <&camera_pins_cam0_rst1>;
	pinctrl-3 = <&camera_pins_cam1_rst0>;
	pinctrl-4 = <&camera_pins_cam1_rst1>;
	pinctrl-5 = <&camera_pins_cam2_rst0>;
	pinctrl-6 = <&camera_pins_cam2_rst1>;
	pinctrl-7 = <&camera_pins_cam2_pnd0>;
	pinctrl-8 = <&camera_pins_cam2_pnd1>;
	pinctrl-9= <&camera_pins_cam_ldo_vcamd_0>;
	pinctrl-10 = <&camera_pins_cam_ldo_vcamd_1>;
	status = "okay";

};
/* CAMERA GPIO end */

/* DISPSYS GPIO standardization */
&pio {

	mtkfb_pins_mode_te_gpio: mode_te_gpio {
		pins_cmd_dat {
			pins = <PINMUX_GPIO44__FUNC_GPIO44>;
		};
	};

	mtkfb_pins_mode_te_te: mode_te_te {
		pins_cmd_dat {
			pins = <PINMUX_GPIO44__FUNC_DSI_TE>;
		};
	};

	mtkfb_pins_lcm_reset0: lcm_rst_out0_gpio {
		pins_cmd_dat {
			pins = <PINMUX_GPIO158__FUNC_GPIO158>;
			slew-rate = <1>;
			output-low;
		};
	};

	mtkfb_pins_lcm_reset1: lcm_rst_out1_gpio {
		pins_cmd_dat {
			pins = <PINMUX_GPIO158__FUNC_GPIO158>;
			slew-rate = <1>;
			output-high;
		};
	};

	mtkfb_pins_lcd_bias_enp0: lcd_bias_enp0_gpio {
		pins_cmd_dat {
			pins = <PINMUX_GPIO12__FUNC_GPIO12>;
			slew-rate = <1>;
			output-low;
		};
	};

	mtkfb_pins_lcd_bias_enp1: lcd_bias_enp1_gpio {
		pins_cmd_dat {
			pins = <PINMUX_GPIO12__FUNC_GPIO12>;
			slew-rate = <1>;
			output-high;
		};
	};

	mtkfb_pins_default: mtkfb_default {
	};

};

&mtkfb {
	pinctrl-names = "default", "mode_te_gpio", "mode_te_te", "lcm_rst_out0_gpio",
	"lcm_rst_out1_gpio", "lcd_bias_enp0_gpio", "lcd_bias_enp1_gpio";
	pinctrl-0 = <&mtkfb_pins_default>;
	pinctrl-1 = <&mtkfb_pins_mode_te_gpio>;
	pinctrl-2 = <&mtkfb_pins_mode_te_te>;
	pinctrl-3 = <&mtkfb_pins_lcm_reset0>;
	pinctrl-4 = <&mtkfb_pins_lcm_reset1>;
	pinctrl-5 = <&mtkfb_pins_lcd_bias_enp0>;
	pinctrl-6 = <&mtkfb_pins_lcd_bias_enp1>;
	partial-update = <1>;
	status = "okay";
};/* DISPSYS GPIO standardization end */

/* FLASHLIGHTS_LM3643 GPIO standardization */
&pio {
	flashlights_lm3643_pins_default: flashlights_default {
	};

	flashlights_lm3643_pins_hwen_high: hwen_high {
		pins_cmd_dat {
			pins = <PINMUX_GPIO8__FUNC_GPIO8>;
			slew-rate = <1>;
			output-high;
		};
	};

	flashlights_lm3643_pins_hwen_low: hwen_low {
		pins_cmd_dat {
			pins = <PINMUX_GPIO8__FUNC_GPIO8>;
			slew-rate = <1>;
			output-low;
		};
	};
};

&flashlights_lm3643 {
	pinctrl-names = "default", "hwen_high", "hwen_low";
	pinctrl-0 = <&flashlights_lm3643_pins_default>;
	pinctrl-1 = <&flashlights_lm3643_pins_hwen_high>;
	pinctrl-2 = <&flashlights_lm3643_pins_hwen_low>;
	status = "okay";
};
/* FLASHLIGHTS_LM3643 GPIO end */

/* IF-PMIC configurations */
&i2c5 {

	s2mu005@3d {
		compatible = "samsung,s2mu005mfd";
		reg = <0x3d>;
		interrupt-parent = <&eintc>;
		interrupts = <8 IRQ_TYPE_EDGE_FALLING>;
		pinctrl-names = "default", "ifpmicirq", "ifpmicrstb";
		pinctrl-0 = <&if_pmic_default &if_pmic_irq &if_pmic_rstb>;
		pinctrl-1 = <&if_pmic_irq>;
		pinctrl-2 = <&if_pmic_rstb>;
		s2mu005,wakeup;
		s2mu005,irq-gpio = <&pio 8 0>;
		debounce = <0 0>;
		status = "okay";

		muic {
			status = "okay";
		};
	};
	s2mu005_fled {
		compatible = "samsung,s2mu005-fled";
		enable = <1 1>;
		rear_flash_current = <900>;
		rear_preflash_current = <175>;
		rear_movie_current = <175>;
		rear_torch_current = <100>;
		front_torch_current = <50>;
		factory_current = <250>;
		s2mu005,torch-gpio = <&pio 116 0x00>;
		s2mu005,flash-gpio = <&pio 115 0x00>;
		pinctrl-names = "fled_default","fled_sleep";
		pinctrl-0 = <&cam_flash_active>;
		pinctrl-1 = <&cam_flash_sleep>;
		S2MU005_FLASH_LED{
			id = <0>;
			ledname = "S2MU005_FLASH_LED";
			brightness = <1200>;
			timeout = <15>;/*reg value:0xF*/
			max_brightness = <1200>;
		};
		S2MU005_TORCH_LED{
			id = <1>;
			ledname = "S2MU005_TORCH_LED";
			brightness = <50>;
			timeout = <15>;/*reg value:0xF*/
			max_brightness = <400>;
		};
	};
};

&pio {
	if_pmic_default: default {
		/* Setting gpio mode to i2c */
		pins_cmd_dat1 {
			pins = <PINMUX_GPIO48__FUNC_SDA_APPM>;
			slew-rate = <0>;
			bias-disable;
		};
		pins_cmd_dat2 {
			pins = <PINMUX_GPIO47__FUNC_SCL_APPM>;
			slew-rate = <0>;
			bias-disable;
		};
	};

	if_pmic_irq: ifpmicirq {
		pins_cmd_dat {
			pins = <PINMUX_GPIO8__FUNC_GPIO8>;
			slew-rate = <0>;
			bias-disable;
		};
	};

	if_pmic_rstb: ifpmicrstb {
		pins_cmd_dat {
			pins = <PINMUX_GPIO13__FUNC_GPIO13>;
			slew-rate = <1>;
			output-high;
			bias-disable;
		};
	};
	cam_flash {
		pins = <PINMUX_GPIO115__FUNC_GPIO115>, <PINMUX_GPIO116__FUNC_GPIO116>;
		num-grp-pins = <2>;
		pin-func = <0>;
		label = "cam_flash";

	cam_flash_active: default {
		pins_cmd_dat {
/*				pins = <PINMUX_GPIO115__FUNC_GPIO115>;	*/
			drive-strength = <0>;	/* 2 MA */
			bias-disable;
			output-low;
		};
	};
	cam_flash_sleep: sleep {
		pins_cmd_dat {
/*				pins = <PINMUX_GPIO116__FUNC_GPIO116>;	*/
			drive-strength = <0>;	/* 2 MA */
			bias-disable;
			output-low;
		};
	};
	};
};
/* IF-PMIC end */

&mt_pmic_vbif28_ldo_reg {
	regulator-default-on = <1>; /* 0:skip, 1: off, 2:on */
	status = "okay";
};

/* FUELGAUGE configurations */
&pio {
	fg_i2c_active: fg_i2c_active {
		pins_cmd_dat1 {
			pins = <PINMUX_GPIO107__FUNC_GPIO107>;	/*fuelgauge sda pin*/
			slew-rate = <0>;
			bias-disable;
		};
		pins_cmd_dat2 {
			pins = <PINMUX_GPIO108__FUNC_GPIO108>;	/*fuelgauge scl pin*/
			slew-rate = <0>;
			bias-disable;
		};
	};

	fg_alert_default: fg_alert_default {
		pins_cmd_dat {
			pins = <PINMUX_GPIO2__FUNC_GPIO2>;
			slew-rate = <0>;
			input-enable;
		};
	};
};

&i2c25 {
	s2mu005-fuelgauge@3b {
		compatible = "samsung,s2mu005-fuelgauge";
		reg = <0x3b>;
		interrupt-parent = <&eintc>;
		pinctrl-names = "default";
		pinctrl-0 = <&fg_i2c_active &fg_alert_default>;
		fuelgauge,irqf = "IRQF_TRIGGER_FALLING + IRQF_ONESHOT + IRQF_NO_SUSPEND";
		fuelgauge,fuel_int = <&pio 2 0>;
		fuelgauge,fuel_alert_soc = <1>;
		fuelgauge,capacity_max = <1000>;
		fuelgauge,capacity_max_margin = <70>;
		fuelgauge,capacity_min = <0>;
		fuelgauge,capacity_calculation_type = <0x1F>;
	};
};
/* FUELGAUGE end */

/*End of this file, DO NOT ADD ANYTHING HERE*/

